# STM32G431C6T6 register map
File version: 1.0
Registers are 32-bit, access not given, reset 0x0 unless marked. A register's access mark holds for its fields unless they carry their own. Offsets are from the block's base; [hi:lo] are bit positions; {n}, {i} and the like mark numbered series.

## FDCAN1
Base 0x40006400
Same registers: FDCAN2 0x40006800, FDCAN3 0x40006C00, FDCANMRAM 0x4000A400, FDCANMRAM 0x4000A800, FDCANMRAM 0x4000AC00
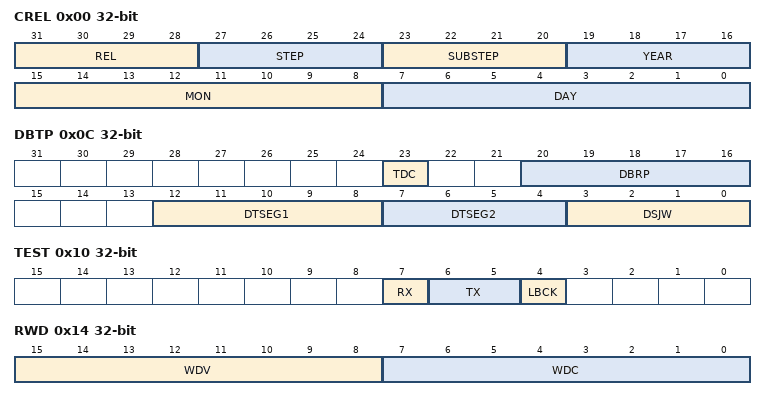
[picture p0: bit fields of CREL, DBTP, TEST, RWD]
0x00 CREL
  [31:28] REL, [27:24] STEP, [23:20] SUBSTEP, [19:16] YEAR, [15:8] MON, [7:0] DAY
0x04 ENDN
  [31:0] ETV
0x0C DBTP
  [23] TDC, [20:16] DBRP, [12:8] DTSEG1, [7:4] DTSEG2, [3:0] DSJW
0x10 TEST
  [7] RX, [6:5] TX, [4] LBCK
0x14 RWD
  [15:8] WDV, [7:0] WDC
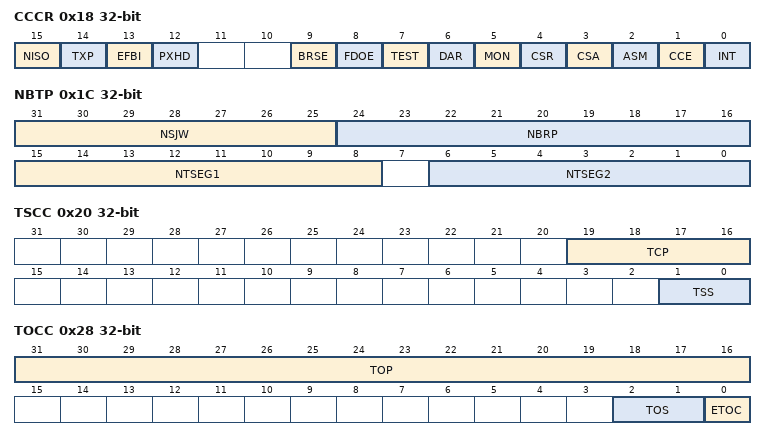
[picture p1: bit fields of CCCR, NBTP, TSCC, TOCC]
0x18 CCCR
  [15] NISO, [14] TXP, [13] EFBI, [12] PXHD, [9] BRSE, [8] FDOE, [7] TEST, [6] DAR, [5] MON, [4] CSR, [3] CSA, [2] ASM, [1] CCE, [0] INT
0x1C NBTP
  [31:25] NSJW, [24:16] NBRP, [15:8] NTSEG1, [6:0] NTSEG2
0x20 TSCC
  [19:16] TCP, [1:0] TSS
0x24 TSCV
  [15:0] TSC
0x28 TOCC
  [31:16] TOP, [2:1] TOS, [0] ETOC
0x2C TOCV
  [15:0] TOC
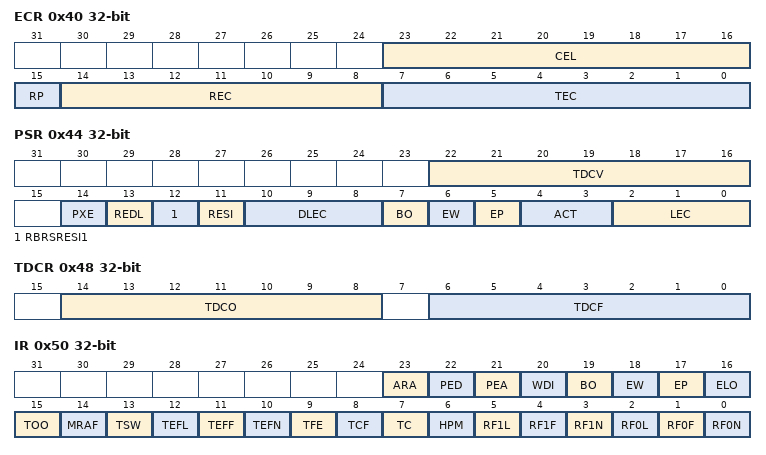
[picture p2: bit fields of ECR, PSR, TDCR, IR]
0x40 ECR
  [23:16] CEL, [15] RP, [14:8] REC, [7:0] TEC
0x44 PSR
  [22:16] TDCV, [14] PXE, [13] REDL, [12] RBRSRESI1, [11] RESI, [10:8] DLEC, [7] BO, [6] EW, [5] EP, [4:3] ACT, [2:0] LEC
0x48 TDCR
  [14:8] TDCO, [6:0] TDCF
0x50 IR
  [23] ARA, [22] PED, [21] PEA, [20] WDI, [19] BO, [18] EW, [17] EP, [16] ELO, [15] TOO, [14] MRAF, [13] TSW, [12] TEFL, [11] TEFF, [10] TEFN, [9] TFE, [8] TCF, [7] TC, [6] HPM, [5] RF1L, [4] RF1F, [3] RF1N, [2] RF0L, [1] RF0F, [0] RF0N
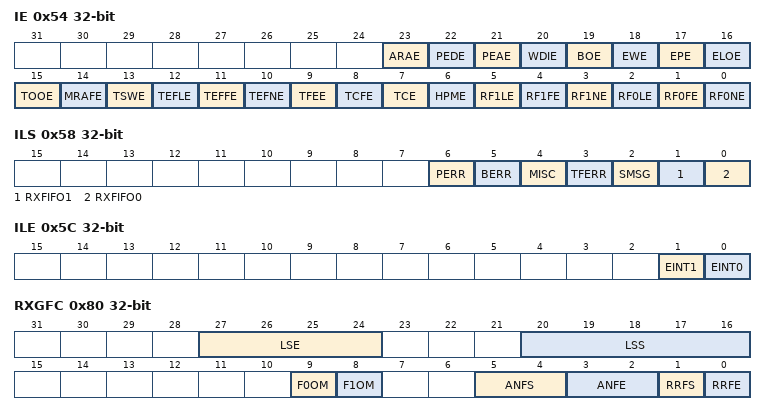
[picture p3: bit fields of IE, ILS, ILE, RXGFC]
0x54 IE
  [23] ARAE, [22] PEDE, [21] PEAE, [20] WDIE, [19] BOE, [18] EWE, [17] EPE, [16] ELOE, [15] TOOE, [14] MRAFE, [13] TSWE, [12] TEFLE, [11] TEFFE, [10] TEFNE, [9] TFEE, [8] TCFE, [7] TCE, [6] HPME, [5] RF1LE, [4] RF1FE, [3] RF1NE, [2] RF0LE, [1] RF0FE, [0] RF0NE
0x58 ILS
  [6] PERR, [5] BERR, [4] MISC, [3] TFERR, [2] SMSG, [1] RXFIFO1, [0] RXFIFO0
0x5C ILE
  [1] EINT1, [0] EINT0
0x80 RXGFC
  [27:24] LSE, [20:16] LSS, [9] F0OM, [8] F1OM, [5:4] ANFS, [3:2] ANFE, [1] RRFS, [0] RRFE
0x84 XIDAM
  [28:0] EIDM
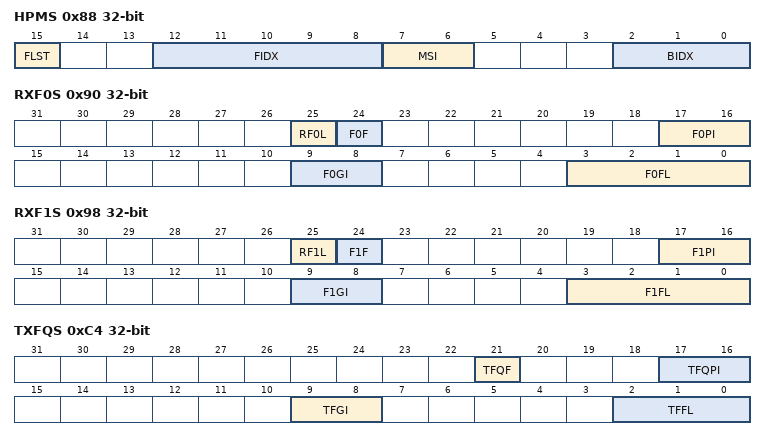
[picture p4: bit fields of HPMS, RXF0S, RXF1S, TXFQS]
0x88 HPMS
  [15] FLST, [12:8] FIDX, [7:6] MSI, [2:0] BIDX
0x90 RXF0S
  [25] RF0L, [24] F0F, [17:16] F0PI, [9:8] F0GI, [3:0] F0FL
0x94 RXF0A
  [2:0] F0AI
0x98 RXF1S
  [25] RF1L, [24] F1F, [17:16] F1PI, [9:8] F1GI, [3:0] F1FL
0x9C RXF1A
  [2:0] F1AI
0xC0 TXBC
  [24] TFQM
0xC4 TXFQS
  [21] TFQF, [17:16] TFQPI, [9:8] TFGI, [2:0] TFFL
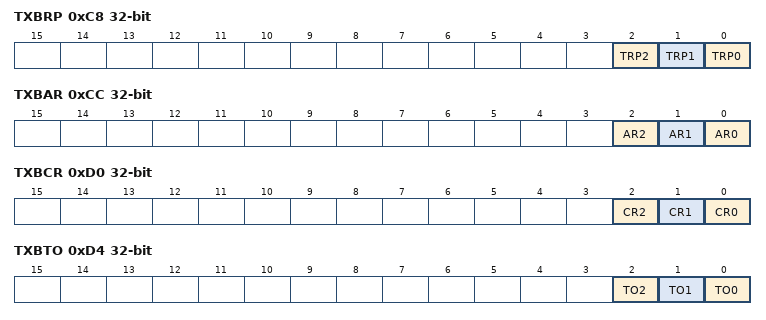
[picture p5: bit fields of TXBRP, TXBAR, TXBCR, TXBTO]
0xC8 TXBRP
  [2] TRP2, [1] TRP1, [0] TRP0
0xCC TXBAR
  [2] AR2, [1] AR1, [0] AR0
0xD0 TXBCR
  [2] CR2, [1] CR1, [0] CR0
0xD4 TXBTO
  [2] TO2, [1] TO1, [0] TO0
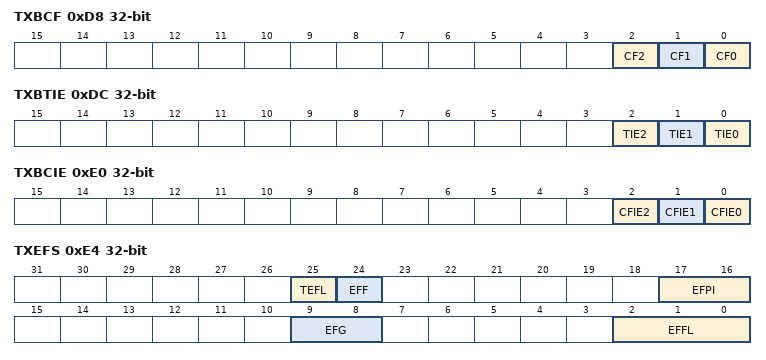
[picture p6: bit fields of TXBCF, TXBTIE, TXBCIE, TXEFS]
0xD8 TXBCF
  [2] CF2, [1] CF1, [0] CF0
0xDC TXBTIE
  [2] TIE2, [1] TIE1, [0] TIE0
0xE0 TXBCIE
  [2] CFIE2, [1] CFIE1, [0] CFIE0
0xE4 TXEFS
  [25] TEFL, [24] EFF, [17:16] EFPI, [9:8] EFG, [2:0] EFFL
0xE8 TXEFA
  [1:0] EFAI
0x100 CKDIV
  [3:0] PDIV

## PWR
Base 0x40007000
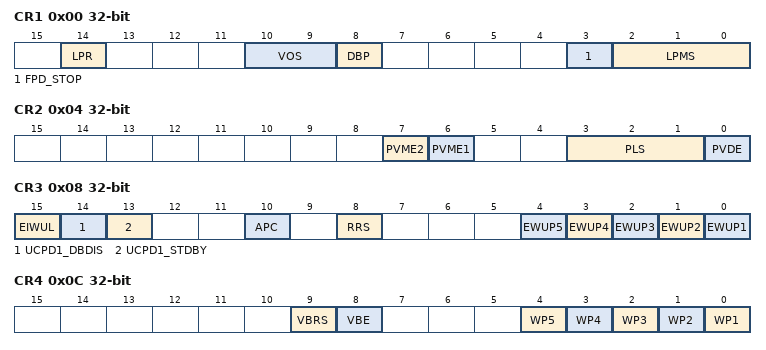
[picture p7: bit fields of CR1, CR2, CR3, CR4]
0x00 CR1
  [14] LPR, [10:9] VOS, [8] DBP, [3] FPD_STOP, [2:0] LPMS
0x04 CR2
  [7] PVME2, [6] PVME1, [3:1] PLS, [0] PVDE
0x08 CR3
  [15] EIWUL, [14] UCPD1_DBDIS, [13] UCPD1_STDBY, [10] APC, [8] RRS, [n-1] EWUP{n} (n=1..5)
0x0C CR4
  [9] VBRS, [8] VBE, [n-1] WP{n} (n=1..5)
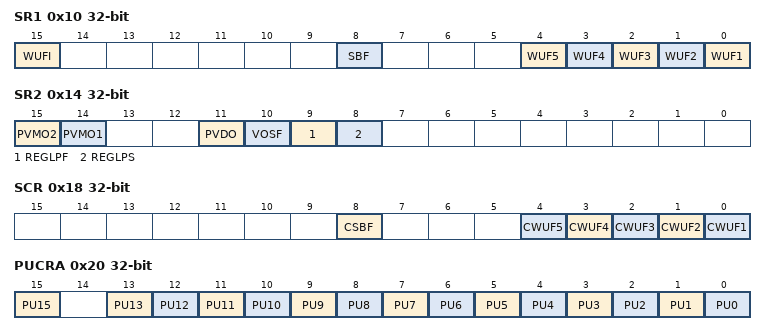
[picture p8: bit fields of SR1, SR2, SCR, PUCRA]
0x10 SR1
  [15] WUFI, [8] SBF, [n-1] WUF{n} (n=1..5)
0x14 SR2
  [15] PVMO2, [14] PVMO1, [11] PVDO, [10] VOSF, [9] REGLPF, [8] REGLPS
0x18 SCR
  [8] CSBF, [n-1] CWUF{n} (n=1..5)
0x20 PUCRA
  [15] PU15, [n] PU{n} (n=0..13)
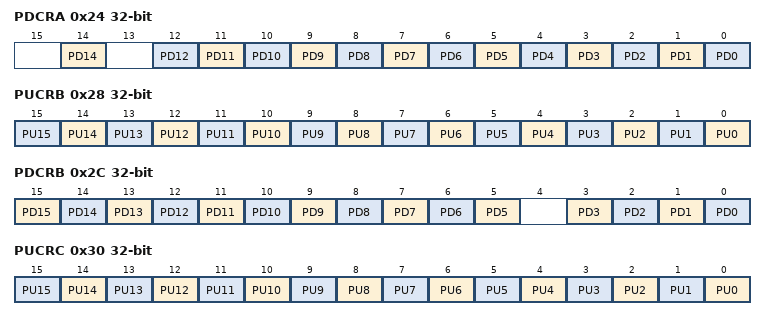
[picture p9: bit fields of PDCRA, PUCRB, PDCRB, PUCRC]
0x24 PDCRA
  [14] PD14, [n] PD{n} (n=0..12)
0x28 PUCRB
  [n] PU{n} (n=0..15)
0x2C PDCRB
  [n] PD{n} (n=5..15), [n] PD{n} (n=0..3)
0x30 PUCRC
  [n] PU{n} (n=0..15)
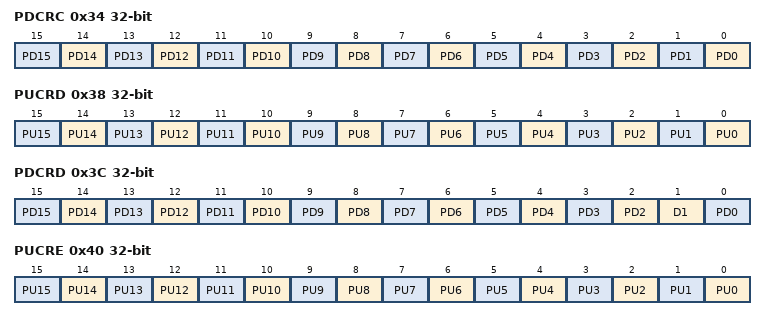
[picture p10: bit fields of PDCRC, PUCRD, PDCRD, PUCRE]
0x34 PDCRC
  [n] PD{n} (n=0..15)
0x38 PUCRD
  [n] PU{n} (n=0..15)
0x3C PDCRD
  [n] PD{n} (n=2..15), [1] D1, [0] PD0
0x40 PUCRE
  [n] PU{n} (n=0..15)
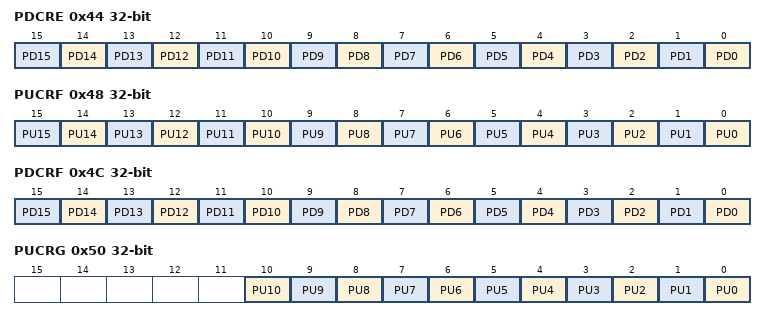
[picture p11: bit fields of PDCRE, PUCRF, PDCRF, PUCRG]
0x44 PDCRE
  [n] PD{n} (n=0..15)
0x48 PUCRF
  [n] PU{n} (n=0..15)
0x4C PDCRF
  [n] PD{n} (n=0..15)
0x50 PUCRG
  [n] PU{n} (n=0..10)
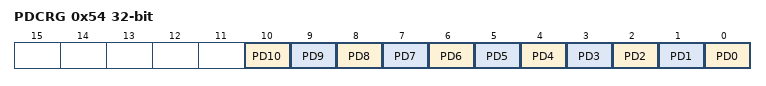
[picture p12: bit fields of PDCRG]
0x54 PDCRG
  [n] PD{n} (n=0..10)
0x80 CR5
  [8] R1MODE

## LPTIM1
Base 0x40007C00
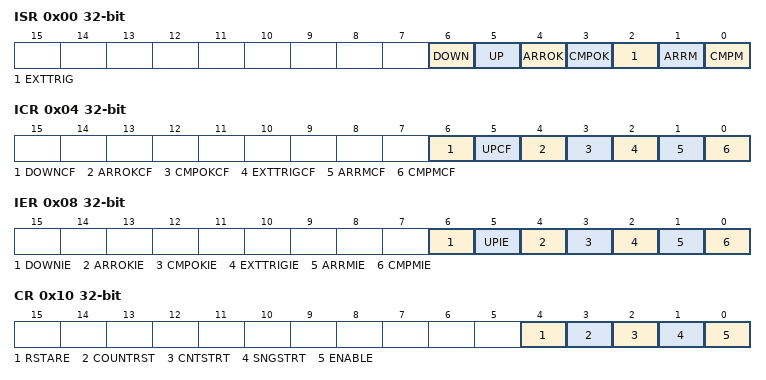
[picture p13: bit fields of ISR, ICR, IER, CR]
0x00 ISR
  [6] DOWN, [5] UP, [4] ARROK, [3] CMPOK, [2] EXTTRIG, [1] ARRM, [0] CMPM
0x04 ICR
  [6] DOWNCF, [5] UPCF, [4] ARROKCF, [3] CMPOKCF, [2] EXTTRIGCF, [1] ARRMCF, [0] CMPMCF
0x08 IER
  [6] DOWNIE, [5] UPIE, [4] ARROKIE, [3] CMPOKIE, [2] EXTTRIGIE, [1] ARRMIE, [0] CMPMIE
0x0C CFGR
  [24] ENC, [23] COUNTMODE, [22] PRELOAD, [21] WAVEPOL, [20] WAVE, [19] TIMOUT, [18:17] TRIGEN, [29:13] TRIGSEL, [11:9] PRESC, [7:6] TRGFLT, [4:3] CKFLT, [2:1] CKPOL, [0] CKSEL
0x10 CR
  [4] RSTARE, [3] COUNTRST, [2] CNTSTRT, [1] SNGSTRT, [0] ENABLE
0x14 CMP
  [15:0] CMP
0x18 ARR
  [15:0] ARR
0x1C CNT
  [15:0] CNT
0x20 OR
  [5:1] IN2, [3:0] IN1
